# M030GAE register map
File version: 1.0
Registers are 32-bit, read-write, reset 0x0 unless marked. A register's access mark holds for its fields unless they carry their own. Offsets are from the block's base; [hi:lo] are bit positions.

## NMI — NMI Register Map
Base 0x40000300
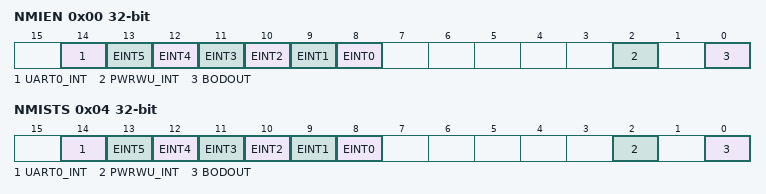
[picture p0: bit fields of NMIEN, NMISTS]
0x00 NMIEN — NMI Source Interrupt Enable Register
  [14] UART0_INT — UART0 NMI Source Enable (Write Protect). Note: This bit is write protected. Refer to the SYS_REGLCTL register.
    0=UART0 NMI source Disabled; 1=UART0 NMI source Enabled
  [13] EINT5 — External Interrupt From PB.7 Pin NMI Source Enable (Write Protect). Note: This bit is write protected. Refer to the SYS_REGLCTL register.
    0=External interrupt from PB.7 pin NMI source Disabled; 1=External interrupt from PB.7 pin NMI source Enabled
  [12] EINT4 — External Interrupt From PB.6 Pin NMI Source Enable (Write Protect). Note: This bit is write protected. Refer to the SYS_REGLCTL register.
    0=External interrupt from PB.6 pin NMI source Disabled; 1=External interrupt from PB.6 pin NMI source Enabled
  [11] EINT3 — External Interrupt From PB.2 Pin NMI Source Enable (Write Protect). Note: This bit is write protected. Refer to the SYS_REGLCTL register.
    0=External interrupt from PB.2 pin NMI source Disabled; 1=External interrupt from PB.2 pin NMI source Enabled
  [10] EINT2 — External Interrupt From PB.3 Pin NMI Source Enable (Write Protect). Note: This bit is write protected. Refer to the SYS_REGLCTL register.
    0=External interrupt from PB.3 pin NMI source Disabled; 1=External interrupt from PB.3 pin NMI source Enabled
  [9] EINT1 — External Interrupt From PB.4 Pin NMI Source Enable (Write Protect). Note: This bit is write protected. Refer to the SYS_REGLCTL register.
    0=External interrupt from PB.4 pin NMI source Disabled; 1=External interrupt from PB.4 pin NMI source Enabled
  [8] EINT0 — External Interrupt From PB.5 Pin NMI Source Enable (Write Protect). Note: This bit is write protected. Refer to the SYS_REGLCTL register.
    0=External interrupt from PB.5 pin NMI source Disabled; 1=External interrupt from PB.5 pin NMI source Enabled
  [2] PWRWU_INT — Power-down Mode Wake-up NMI Source Enable (Write Protect). Note: This bit is write protected. Refer to the SYS_REGLCTL register.
    0=Power-down mode wake-up NMI source Disabled; 1=Power-down mode wake-up NMI source Enabled
  [0] BODOUT — BOD NMI Source Enable (Write Protect). Note: This bit is write protected. Refer to the SYS_REGLCTL register.
    0=BOD NMI source Disabled; 1=BOD NMI source Enabled
0x04 NMISTS ro — NMI Source Interrupt Status Register
  [14] UART0_INT — UART0 Interrupt Flag (Read Only)
    0=UART0 interrupt is deasserted; 1=UART0 interrupt is asserted
  [13] EINT5 — External Interrupt From PB.7 Pin Interrupt Flag (Read Only)
    0=External Interrupt from PB.7 interrupt is deasserted; 1=External Interrupt from PB.7 interrupt is asserted
  [12] EINT4 — External Interrupt From PB.6 Pin Interrupt Flag (Read Only)
    0=External Interrupt from PB.6 interrupt is deasserted; 1=External Interrupt from PB.6 interrupt is asserted
  [11] EINT3 — External Interrupt From PB.2 Pin Interrupt Flag (Read Only)
    0=External Interrupt from PB.2 interrupt is deasserted; 1=External Interrupt from PB.2 interrupt is asserted
  [10] EINT2 — External Interrupt From PB.3 Pin Interrupt Flag (Read Only)
    0=External Interrupt from PB.3 interrupt is deasserted; 1=External Interrupt from PB.3 interrupt is asserted
  [9] EINT1 — External Interrupt From PB.4 Pin Interrupt Flag (Read Only)
    0=External Interrupt from PB.4 interrupt is deasserted; 1=External Interrupt from PB.4 interrupt is asserted
  [8] EINT0 — External Interrupt From PB.5 Pin Interrupt Flag (Read Only)
    0=External Interrupt from PB.5 interrupt is deasserted; 1=External Interrupt from PB.5 interrupt is asserted
  [2] PWRWU_INT — Power-down Mode Wake-up Interrupt Flag (Read Only)
    0=Power-down mode wake-up interrupt is deasserted; 1=Power-down mode wake-up interrupt is asserted
  [0] BODOUT — BOD Interrupt Flag (Read Only)
    0=BOD interrupt is deasserted; 1=BOD interrupt is asserted

## CRC — CRC Register Map
Base 0x40031000
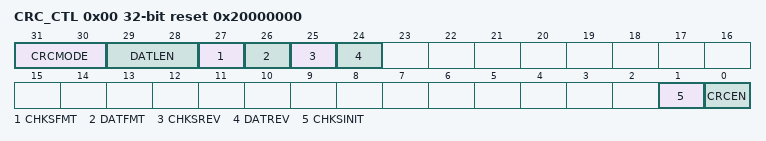
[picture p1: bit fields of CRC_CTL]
0x00 CRC_CTL reset 0x20000000 — CRC Control Register
  [31:30] CRCMODE — CRC Polynomial Mode. This field indicates the CRC operation polynomial mode.
    0=CRC-CCITT Polynomial mode; 1=CRC-8 Polynomial mode; 2=CRC-16 Polynomial mode; 3=CRC-32 Polynomial mode
  [29:28] DATLEN — CPU Write Data Length. This field indicates the write data length. Note: When the write data length is 8-bit mode, the valid data in CRC_DAT register is only DATA[7:0] bits; if the write data length is 16-bit mode, the valid data in CRC_DAT register is only DATA[15:0].
    0=Data length is 8-bit mode; 1=Data length is 16-bit mode. Data length is 32-bit mode
  [27] CHKSFMT — Checksum 1's Complement. This bit is used to enable the 1's complement function for checksum result in CRC_CHECKSUM register.
    0=1's complement for CRC checksum Disabled; 1=1's complement for CRC checksum Enabled
  [26] DATFMT — Write Data 1's Complement. This bit is used to enable the 1's complement function for write data value in CRC_DAT register.
    0=1's complement for CRC writes data in Disabled; 1=1's complement for CRC writes data in Enabled
  [25] CHKSREV — Checksum Bit Order Reverse. This bit is used to enable the bit order reverse function for checksum result in CRC_CHECKSUM register. Note: If the checksum result is 0xDD7B0F2E, the bit order reverse for CRC checksum is 0x74F0DEBB.
    0=Bit order reverse for CRC checksum Disabled; 1=Bit order reverse for CRC checksum Enabled
  [24] DATREV — Write Data Bit Order Reverse. This bit is used to enable the bit order reverse function per byte for write data value in CRC_DAT register. Note: If the write data is 0xAABBCCDD, the bit order reverse for CRC write data in is 0x55DD33BB.
    0=Bit order reversed for CRC write data in Disabled; 1=Bit order reversed for CRC write data in Enabled (per byte)
  [1] CHKSINIT — Checksum Initialization. Note: This bit will be cleared automatically.
    0=No effect; 1=Initial checksum value by auto reload CRC_SEED register value to CRC_CHECKSUM register value
  [0] CRCEN — CRC Channel Enable Bit
    0=No effect; 1=CRC operation Enabled
0x04 CRC_DAT — CRC Write Data Register
  [31:0] DATA — CRC Write Data Bits. User can write data directly by CPU mode or use PDMA function to write data to this field to perform CRC operation. Note: When the write data length is 8-bit mode, the valid data in CRC_DAT register is only DATA[7:0] bits; if the write data length is 16-bit mode, the valid data in CRC_DAT register is only DATA[15:0].
0x08 CRC_SEED reset 0xFFFFFFFF
  [31:0] SEED — CRC Seed Value. This field indicates the CRC seed value. Note: This field will be reloaded as checksum initial value (CRC_CHECKSUM register) after perform CHKSINIT (CRC_CTL[1]).
0x0C CRC_CHECKSUM ro reset 0xFFFFFFFF
  [31:0] CHECKSUM — CRC Checksum Results. This field indicates the CRC checksum result.
0x10 CRC_POLYNOMIAL
  [31:0] POLYNOMIAL — CRC Polynomial Value Results. This field indicates the value of CRC polynomial.
